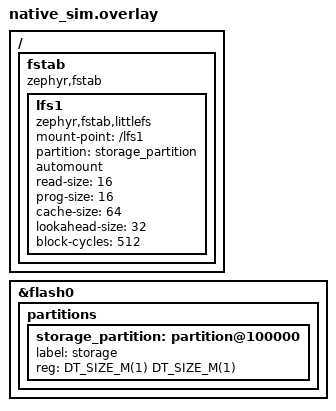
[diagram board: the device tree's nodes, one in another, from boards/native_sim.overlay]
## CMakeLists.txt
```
# SPDX-License-Identifier: Apache-2.0

cmake_minimum_required(VERSION 3.20.0)

if(BOARD STREQUAL "nrf52840dk/nrf52840")
    if(NOT SHIELD)
        set(SHIELD golioth_esp_at)
        message(WARNING
            "Implicitly selecting golioth_esp_at SHIELD. This behavior is\
             deprecated. Specify '--shield golioth_esp_at' explicitly with\
             'west build' invocation.")
    endif()
endif()

find_package(Zephyr REQUIRED HINTS $ENV{ZEPHYR_BASE})
project(cert_provisioning)

target_sources(app PRIVATE src/main.c)

add_custom_command(
    OUTPUT ${ZEPHYR_BINARY_DIR}/lfs.hex
    COMMAND ${PYTHON_EXECUTABLE}
      ${CMAKE_CURRENT_SOURCE_DIR}/generate-lfs-image.py
      --build-dir ${APPLICATION_BINARY_DIR}
)

add_custom_target(
    lfs ALL
    DEPENDS ${ZEPHYR_BINARY_DIR}/lfs.hex
)
```

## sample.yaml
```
sample:
  description: Provision certificates onto a device
  name: certificate_provisioning
common:
  tags:
    - golioth
    - socket
    - goliothd
tests:
  sample.golioth.certificate_provisioning:
    harness: pytest
    tags:
      - golioth
      - socket
      - goliothd
    timeout: 180
    extra_configs:
      - CONFIG_GOLIOTH_SAMPLE_TWISTER_TEST=y
      - arch:posix:CONFIG_NATIVE_UART_0_ON_STDINOUT=y
    platform_allow:
      - frdm_rw612
      - native_sim
      - native_sim/native/64
      - nrf9160dk/nrf9160/ns
      - nucleo_h563zi/stm32h563xx
  sample.golioth.certificate_provisioning.psa_crypto:
    harness: pytest
    tags:
      - golioth
      - socket
      - goliothd
    timeout: 180
    extra_configs:
      - CONFIG_MBEDTLS_PSA_CRYPTO_C=y
      - CONFIG_GOLIOTH_SAMPLE_TWISTER_TEST=y
      - arch:posix:CONFIG_NATIVE_UART_0_ON_STDINOUT=y
      - arch:posix:CONFIG_MCUMGR_TRANSPORT_UDP_PORT=1347
    platform_allow:
      - frdm_rw612
      - native_sim
      - native_sim/native/64
      - nrf9160dk/nrf9160/ns
      - nucleo_h563zi/stm32h563xx
```

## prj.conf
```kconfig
# Application
CONFIG_GOLIOTH_SAMPLE_COMMON=y
CONFIG_LOG_BACKEND_GOLIOTH=y

# Golioth Firmware SDK with all dependencies
CONFIG_GOLIOTH_FIRMWARE_SDK=y

# Enable flash operations
CONFIG_FLASH=y
CONFIG_FLASH_MAP=y

# Enable the LittleFS file system
CONFIG_FILE_SYSTEM=y
# init before wifi credentials
CONFIG_FILE_SYSTEM_INIT_PRIORITY=89
CONFIG_FILE_SYSTEM_LITTLEFS=y
CONFIG_FILE_SYSTEM_SHELL=y
CONFIG_HEAP_MEM_POOL_SIZE=4096

# Add 256 bytes to accommodate upload command (lfs_stat overflows)
CONFIG_SYSTEM_WORKQUEUE_STACK_SIZE=2304

# Enable mcumgr
CONFIG_ZCBOR=y
CONFIG_MCUMGR=y

# Enable console with mcumgr pass through
CONFIG_CONSOLE=y
CONFIG_UART_CONSOLE=y
CONFIG_UART_CONSOLE_MCUMGR=y

# Enable the shell mcumgr transport. This allows SMP messages to pass
# through the shell to the mgmt subsystem.
CONFIG_SHELL=y
CONFIG_SHELL_BACKEND_SERIAL=y
CONFIG_BASE64=y
CONFIG_MCUMGR_TRANSPORT_SHELL=y

# Enable file system commands
CONFIG_MCUMGR_GRP_FS=y

# Enable shell commands over SMP
CONFIG_SHELL_BACKEND_DUMMY=y
CONFIG_MCUMGR_GRP_SHELL=y

# Some mgmt command handlers require a large stack.
CONFIG_MAIN_STACK_SIZE=2048

# Enable certificate authentication.
CONFIG_GOLIOTH_AUTH_METHOD_CERT=y

# Enable `log halt` and `log go` commands
CONFIG_LOG_CMDS=y

# If runtime-settings are enabled, use the file storage-backend
CONFIG_SETTINGS_FILE=y
CONFIG_SETTINGS_FILE_PATH="/lfs1/settings"
```

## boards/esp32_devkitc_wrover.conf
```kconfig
CONFIG_WIFI=y
CONFIG_HEAP_MEM_POOL_SIZE=49152
CONFIG_ESP_HEAP_MEM_POOL_REGION_1_SIZE=32768

CONFIG_NET_L2_ETHERNET=y

CONFIG_NEWLIB_LIBC=y

CONFIG_NET_DHCPV4=y

CONFIG_MBEDTLS_ENTROPY_ENABLED=y
CONFIG_MBEDTLS_KEY_EXCHANGE_ECDHE_ECDSA_ENABLED=y
CONFIG_MBEDTLS_ECP_ALL_ENABLED=y

CONFIG_ESP32_WIFI_STA_AUTO_DHCPV4=y

CONFIG_NET_L2_WIFI_SHELL=y
CONFIG_GOLIOTH_SAMPLE_WIFI=y

# https://github.com/zephyrproject-rtos/zephyr/issues/63823
CONFIG_POSIX_FS=n
```

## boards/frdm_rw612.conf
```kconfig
CONFIG_GOLIOTH_SAMPLE_DHCP_BIND=y
CONFIG_NET_DHCPV4=y
CONFIG_BUILD_OUTPUT_HEX=y

# Needed for certificate auth
CONFIG_NET_BUF_DATA_SIZE=512
CONFIG_NET_SOCKETS_CONNECT_TIMEOUT=6000
```

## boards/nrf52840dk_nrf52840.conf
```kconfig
# WiFi
CONFIG_WIFI=y
CONFIG_WIFI_ESP_AT=y
CONFIG_WIFI_ESP_AT_MDM_RX_BUF_COUNT=40
CONFIG_WIFI_ESP_AT_CIPDINFO_USE=y
CONFIG_WIFI_ESP_AT_DNS_USE=y

CONFIG_NET_L2_WIFI_SHELL=y
CONFIG_GOLIOTH_SAMPLE_WIFI=y

# MCU Manager
CONFIG_MCUBOOT_BOOTUTIL_LIB=y
CONFIG_MCUMGR_MGMT_NOTIFICATION_HOOKS=y
CONFIG_MCUMGR_GRP_FS_FILE_ACCESS_HOOK=y

# Allow reboot from shell after loading certificates
CONFIG_REBOOT=y

CONFIG_NET_BUF_DATA_SIZE=256
CONFIG_NET_PKT_TX_COUNT=10

# DTLS handshake timeout
CONFIG_NET_SOCKETS_CONNECT_TIMEOUT=30000
```

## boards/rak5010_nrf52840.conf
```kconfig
CONFIG_UART_ASYNC_API=y
CONFIG_MODEM_CELLULAR_APN="internet"

# USB
CONFIG_USB_DEVICE_STACK_NEXT=y
CONFIG_USBD_CDC_ACM_CLASS=y
CONFIG_CDC_ACM_SERIAL_PID=0x0004
CONFIG_CDC_ACM_SERIAL_PRODUCT_STRING="RAK5010 Zephyr"
CONFIG_CDC_ACM_SERIAL_INITIALIZE_AT_BOOT=y

CONFIG_UART_CONSOLE=y
CONFIG_UART_LINE_CTRL=y
CONFIG_LOG_BACKEND_RTT=n
CONFIG_USBD_LOG_LEVEL_OFF=y
CONFIG_USBD_CDC_ACM_LOG_LEVEL_OFF=y
CONFIG_UDC_DRIVER_LOG_LEVEL_OFF=y

# Networking
CONFIG_NETWORKING=y
CONFIG_NET_NATIVE=y
CONFIG_NET_L2_PPP=y
CONFIG_NET_IPV4=y
CONFIG_NET_UDP=y
CONFIG_NET_SOCKETS=y
CONFIG_NET_CONTEXT_RCVTIMEO=y

# DTLS handshake timeout
CONFIG_NET_SOCKETS_CONNECT_TIMEOUT=30000

# Modem driver
CONFIG_MODEM=y
CONFIG_MODEM_CELLULAR=y
CONFIG_MODEM_CMUX_WORK_BUFFER_SIZE=1024
```

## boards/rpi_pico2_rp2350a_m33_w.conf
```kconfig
CONFIG_NETWORKING=y
CONFIG_TEST_RANDOM_GENERATOR=y

CONFIG_NET_DHCPV4=y

CONFIG_NET_IPV4=y
CONFIG_NET_IPV6=n

CONFIG_NET_BUF_DATA_SIZE=256

CONFIG_WIFI=y
CONFIG_WIFI_LOG_LEVEL_ERR=y
CONFIG_NET_L2_WIFI_SHELL=y
CONFIG_GOLIOTH_SAMPLE_WIFI=y

CONFIG_MBEDTLS_HAVE_TIME_DATE=y

# DTLS handshake timeout
CONFIG_NET_SOCKETS_CONNECT_TIMEOUT=30000
```

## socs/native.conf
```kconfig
# Use offloaded sockets using host BSD sockets
CONFIG_ETH_DRIVER=n
CONFIG_ETH_NATIVE_POSIX=n
CONFIG_NET_DRIVERS=y
CONFIG_NET_SOCKETS=y
CONFIG_NET_SOCKETS_OFFLOAD=y
CONFIG_NET_NATIVE_OFFLOADED_SOCKETS=y
CONFIG_HEAP_MEM_POOL_SIZE=1024

# Use embedded libc to use Zephyr's eventfd instead of host eventfd
CONFIG_PICOLIBC=y

# Static networking
CONFIG_NET_CONFIG_LOG_LEVEL_DBG=y
CONFIG_NET_CONFIG_SETTINGS=y
CONFIG_NET_CONFIG_NEED_IPV4=y
CONFIG_NET_CONFIG_MY_IPV4_ADDR="192.0.2.1"
CONFIG_NET_CONFIG_MY_IPV4_GW="192.0.2.2"
CONFIG_NET_CONFIG_PEER_IPV4_ADDR="192.0.2.2"

# Golioth logging backend requirement
CONFIG_LOG_MODE_DEFERRED=y

# mcumgr over UDP
CONFIG_MCUMGR_TRANSPORT_SHELL=n
CONFIG_MCUMGR_TRANSPORT_UDP=y
CONFIG_MCUMGR_TRANSPORT_UDP_STACK_SIZE=2048
CONFIG_NET_SOCKETS_POLL_MAX=4
```

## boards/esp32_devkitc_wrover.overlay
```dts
/ {
	fstab {
		compatible = "zephyr,fstab";
		lfs1: lfs1 {
			compatible = "zephyr,fstab,littlefs";
			mount-point = "/lfs1";
			partition = <&storage_partition>;
			automount;
			read-size = <16>;
			prog-size = <16>;
			cache-size = <64>;
			lookahead-size = <32>;
			block-cycles = <512>;
		};
	};
};

&wifi {
	status = "okay";
};

&storage_partition {
	reg = <0x00250000 0x00008000>;
};
```

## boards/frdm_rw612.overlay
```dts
/ {
	fstab {
		compatible = "zephyr,fstab";
		lfs1: lfs1 {
			compatible = "zephyr,fstab,littlefs";
			mount-point = "/lfs1";
			partition = <&storage_partition>;
			automount;
			read-size = <16>;
			prog-size = <16>;
			cache-size = <64>;
			lookahead-size = <32>;
			block-cycles = <512>;
		};
	};
};
```

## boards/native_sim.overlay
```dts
/ {
	fstab {
		compatible = "zephyr,fstab";
		lfs1: lfs1 {
			compatible = "zephyr,fstab,littlefs";
			mount-point = "/lfs1";
			partition = <&storage_partition>;
			automount;
			read-size = <16>;
			prog-size = <16>;
			cache-size = <64>;
			lookahead-size = <32>;
			block-cycles = <512>;
		};
	};
};

/delete-node/ &storage_partition;

&flash0 {
	partitions {
		storage_partition: partition@100000 {
			label = "storage";
			reg = <DT_SIZE_M(1) DT_SIZE_M(1)>;
		};
	};
};
```

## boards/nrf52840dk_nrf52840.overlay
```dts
/*
 * Copyright (C) 2023 Golioth, Inc.
 *
 * SPDX-License-Identifier: Apache-2.0
 */

/ {
	fstab {
		compatible = "zephyr,fstab";
		lfs1: lfs1 {
			compatible = "zephyr,fstab,littlefs";
			mount-point = "/lfs1";
			partition = <&storage_partition>;
			automount;
			read-size = <16>;
			prog-size = <16>;
			cache-size = <64>;
			lookahead-size = <32>;
			block-cycles = <512>;
		};
	};
};
```

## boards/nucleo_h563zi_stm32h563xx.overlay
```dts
/ {
	fstab {
		compatible = "zephyr,fstab";
		lfs1: lfs1 {
			compatible = "zephyr,fstab,littlefs";
			mount-point = "/lfs1";
			partition = <&storage_partition>;
			automount;
			read-size = <32>;
			prog-size = <32>;
			cache-size = <64>;
			lookahead-size = <32>;
			block-cycles = <512>;
		};
	};
};
```

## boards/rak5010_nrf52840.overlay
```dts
/ {

	fstab {
		compatible = "zephyr,fstab";
		lfs1: lfs1 {
			compatible = "zephyr,fstab,littlefs";
			mount-point = "/lfs1";
			partition = <&storage_partition>;
			automount;
			read-size = <16>;
			prog-size = <16>;
			cache-size = <64>;
			lookahead-size = <32>;
			block-cycles = <512>;
		};
	};

	chosen {
		zephyr,console = &cdc_acm_uart0;
		zephyr,shell-uart = &cdc_acm_uart0;
	};

};

&zephyr_udc0 {
	cdc_acm_uart0: cdc_acm_uart0 {
		compatible = "zephyr,cdc-acm-uart";
	};
};
```

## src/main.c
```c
/*
 * Copyright (c) 2023-2025 Golioth, Inc.
 *
 * SPDX-License-Identifier: Apache-2.0
 */

#include <zephyr/logging/log.h>
LOG_MODULE_REGISTER(cert_provisioning, LOG_LEVEL_DBG);

#include <golioth/client.h>
#include <samples/common/net_connect.h>
#include <zephyr/kernel.h>
#include <zephyr/net/coap.h>
#include <zephyr/device.h>
#include <zephyr/fs/fs.h>

#define CRT_PATH "/lfs1/credentials/crt.der"
#define KEY_PATH "/lfs1/credentials/key.der"

static const uint8_t tls_ca_crt[] = {
#include "golioth-systemclient-ca_crt.inc"
};

static const uint8_t tls_secondary_ca_crt[] = {
#if CONFIG_GOLIOTH_SECONDARY_CA_CRT
#include "golioth-systemclient-secondary_ca_crt.inc"
#endif
};

struct golioth_client *client;
static K_SEM_DEFINE(connected, 0, 1);

static void on_client_event(struct golioth_client *client,
                            enum golioth_client_event event,
                            void *arg)
{
    bool is_connected = (event == GOLIOTH_CLIENT_EVENT_CONNECTED);
    if (is_connected)
    {
        k_sem_give(&connected);
    }
    LOG_INF("Golioth client %s", is_connected ? "connected" : "disconnected");
}

static int load_credential_from_fs(const char *path, uint8_t **buf_p, size_t *buf_len)
{
    struct fs_file_t file;
    struct fs_dirent dirent;

    fs_file_t_init(&file);

    int err = fs_stat(path, &dirent);

    if (err < 0)
    {
        LOG_WRN("Could not stat %s, err: %d", path, err);
        goto finish;
    }
    if (dirent.type != FS_DIR_ENTRY_FILE)
    {
        LOG_ERR("%s is not a file", path);
        err = -EISDIR;
        goto finish;
    }
    if (dirent.size == 0)
    {
        LOG_ERR("%s is an empty file", path);
        err = -EINVAL;
        goto finish;
    }


    err = fs_open(&file, path, FS_O_READ);

    if (err < 0)
    {
        LOG_ERR("Could not open %s", path);
        goto finish;
    }

    /* NOTE: *buf_p is used directly by the TLS Credentials library, and so must remain
     * allocated for the life of the program.
     */

    free(*buf_p);
    *buf_p = malloc(dirent.size);

    if (*buf_p == NULL)
    {
        LOG_ERR("Could not allocate space to read credential");
        err = -ENOMEM;
        goto finish_with_file;
    }

    err = fs_read(&file, *buf_p, dirent.size);

    if (err < 0)
    {
        LOG_ERR("Could not read %s, err: %d", path, err);
        free(*buf_p);
        goto finish_with_file;
    }

    LOG_INF("Read %d bytes from %s", dirent.size, path);

    /* Set the size of the allocated buffer */
    *buf_len = dirent.size;

finish_with_file:
    fs_close(&file);

finish:
    return err;
}

int main(void)
{
    int counter = 0;

    LOG_DBG("Start certificate provisioning sample");

    net_connect();

    uint8_t *tls_client_crt = NULL;
    uint8_t *tls_client_key = NULL;
    size_t tls_client_crt_len, tls_client_key_len;

    while (1)
    {
        int ret = load_credential_from_fs(CRT_PATH, &tls_client_crt, &tls_client_crt_len);
        if (ret > 0)
        {
            ret = load_credential_from_fs(KEY_PATH, &tls_client_key, &tls_client_key_len);
            if (ret > 0)
            {
                break;
            }
        }

        k_sleep(K_SECONDS(5));
    }

    if (tls_client_crt != NULL && tls_client_key != NULL)
    {
        struct golioth_client_config client_config = {
            .credentials =
                {
                    .auth_type = GOLIOTH_TLS_AUTH_TYPE_PKI,
                    .pki =
                        {
                            .ca_cert = tls_ca_crt,
                            .ca_cert_len = sizeof(tls_ca_crt),
                            .public_cert = tls_client_crt,
                            .public_cert_len = tls_client_crt_len,
                            .private_key = tls_client_key,
                            .private_key_len = tls_client_key_len,
                            .secondary_ca_cert = tls_secondary_ca_crt,
                            .secondary_ca_cert_len = sizeof(tls_secondary_ca_crt),
                        },
                },
        };

        client = golioth_client_create(&client_config);

        golioth_client_register_event_callback(client, on_client_event, NULL);
    }
    else
    {
        LOG_ERR("Error reading certificate credentials from filesystem");
    }

    k_sem_take(&connected, K_FOREVER);

    while (true)
    {
        LOG_INF("Sending hello! %d", counter);

        ++counter;
        k_sleep(K_SECONDS(5));
    }

    return 0;
}
```
